# TMS320F280049 register map
Vendor: Texas Instruments; Series: C2000 F28004x; File version: 0.2.0-generated
Registers are 16-bit, read-write, reset 0x0 unless marked. A register's access mark holds for its fields unless they carry their own. Offsets are from the block's base; [hi:lo] are bit positions.

## ROMWAITSTATEREGS — ROM WAIT STATE Registers
Base 0x000BEA80
0x00 ROMWAITSTATE 32-bit — ROM Wait State Configuration Register
  [0] WSDISABLE — ROM Wait State Enable/Disable Control

## FLASHCTRLREGS — FLASH CTRL Registers
Base 0x000BF000
0x00 FRDCNTL 32-bit — Flash Read Control Register
  [14:11] RWAIT — Random Read Waitstate
0x3C FBAC 32-bit — Flash Bank Access Control Register
  [22:15] BAGP — Bank Active Grace Period
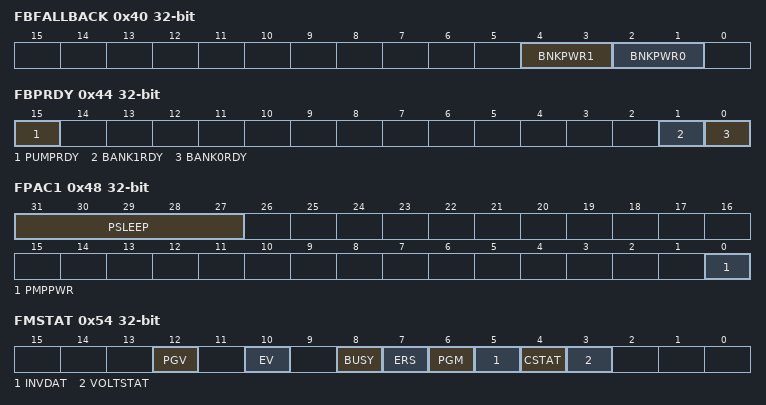
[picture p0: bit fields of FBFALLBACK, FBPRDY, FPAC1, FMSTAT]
0x40 FBFALLBACK 32-bit — Flash Bank Fallback Power Register
  [4:3] BNKPWR1 — Bank Power Mode of BANK1
  [2:1] BNKPWR0 — Bank Power Mode of BANK0
0x44 FBPRDY 32-bit — Flash Bank Pump Ready Register
  [15] PUMPRDY — Flash Pump Active Power Mode
  [1] BANK1RDY — Flash Bank Active Power State
  [0] BANK0RDY — Flash Bank Active Power State
0x48 FPAC1 32-bit — Flash Pump Access Control Register 1
  [31:27] PSLEEP — Pump Sleep Down Count
  [0] PMPPWR — Charge Pump Fallback Power Mode
0x4C FPAC2 32-bit — Flash Pump Access Control Register 2
  [30:15] PAGP — Pump Active Grace Period
0x54 FMSTAT 32-bit — Flash Module Status Register
  [12] PGV — Programming Verify Status
  [10] EV — Erase Verify Status
  [8] BUSY — Busy Bit
  [7] ERS — Erase Operation Status
  [6] PGM — Program Operation Status
  [5] INVDAT — Invalid Data
  [4] CSTAT — Command Fail Status
  [3] VOLTSTAT — Flash Pump Power Status
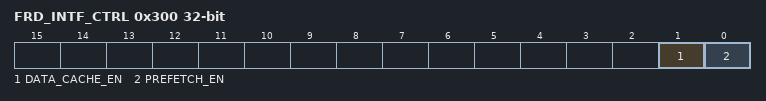
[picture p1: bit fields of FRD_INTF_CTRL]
0x300 FRD_INTF_CTRL 32-bit — Flash Read Interface Control Register
  [1] DATA_CACHE_EN — Data Cache Enable
  [0] PREFETCH_EN — Prefetch Enable

## FLASHECCREGS — FLASH ECC Registers
Base 0x000BF600
0x00 ECC_ENABLE 32-bit
  [6:3] ENABLE — Enable ECC
0x04 SINGLE_ERR_ADDR_LOW 32-bit — Single Error Address Low
  [31] ERR_ADDR_L — Lower 64 bit Single Bit Error Address
0x08 SINGLE_ERR_ADDR_HIGH 32-bit — Single Error Address High
  [31] ERR_ADDR_H — Upper 64 bit Single Bit Error Address
0x0C UNC_ERR_ADDR_LOW 32-bit — Uncorrectable Error Address Low
  [31] UNC_ERR_ADDR_L — Lower 64 bit Uncorrectable Error Address
0x10 UNC_ERR_ADDR_HIGH 32-bit — Uncorrectable Error Address High
  [31] UNC_ERR_ADDR_H — Upper 64 bit Uncorrectable Error Address
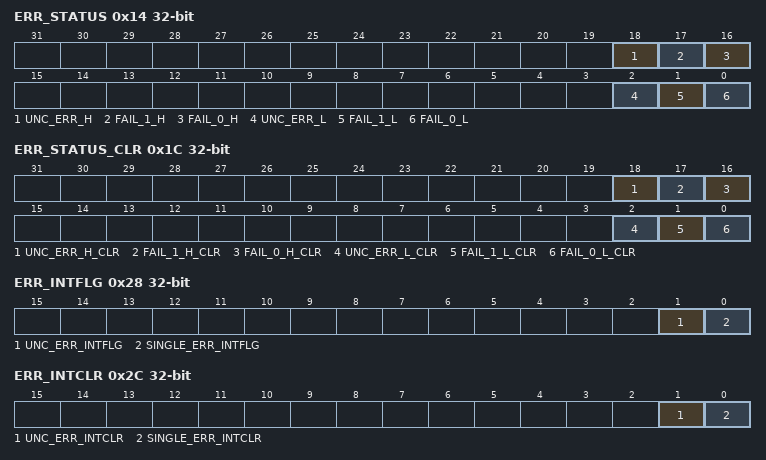
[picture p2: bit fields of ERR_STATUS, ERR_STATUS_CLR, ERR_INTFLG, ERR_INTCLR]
0x14 ERR_STATUS 32-bit — Error Status
  [18] UNC_ERR_H — Upper 64 bits Uncorrectable error occurred
  [17] FAIL_1_H — Upper 64bits Single Bit Error Corrected Value 1
  [16] FAIL_0_H — Upper 64bits Single Bit Error Corrected Value 0
  [2] UNC_ERR_L — Lower 64 bits Uncorrectable error occurred
  [1] FAIL_1_L — Lower 64bits Single Bit Error Corrected Value 1
  [0] FAIL_0_L — Lower 64bits Single Bit Error Corrected Value 0
0x18 ERR_POS 32-bit — Error Position
  [24] ERR_TYPE_H — Error Type in upper 64 bits
  [26:21] ERR_POS_H — Bit Position of Single bit Error in upper 64 bits
  [8] ERR_TYPE_L — Error Type in lower 64 bits
  [10:5] ERR_POS_L — Bit Position of Single bit Error in lower 64 bits
0x1C ERR_STATUS_CLR 32-bit — Error Status Clear
  [18] UNC_ERR_H_CLR — Upper 64 bits Uncorrectable error occurred Clear
  [17] FAIL_1_H_CLR — Upper 64bits Single Bit Error Corrected Value 1 Clear
  [16] FAIL_0_H_CLR — Upper 64bits Single Bit Error Corrected Value 0 Clear
  [2] UNC_ERR_L_CLR — Lower 64 bits Uncorrectable error occurred Clear
  [1] FAIL_1_L_CLR — Lower 64bits Single Bit Error Corrected Value 1 Clear
  [0] FAIL_0_L_CLR — Lower 64bits Single Bit Error Corrected Value 0 Clear
0x20 ERR_CNT 32-bit — Error Control
  [30:15] ERR_CNT — Error counter
0x24 ERR_THRESHOLD 32-bit — Error Threshold
  [30:15] ERR_THRESHOLD
0x28 ERR_INTFLG 32-bit — Error Interrupt Flag
  [1] UNC_ERR_INTFLG — Uncorrectable Interrupt Flag
  [0] SINGLE_ERR_INTFLG — Single Error Interrupt Flag
0x2C ERR_INTCLR 32-bit — Error Interrupt Flag Clear
  [1] UNC_ERR_INTCLR — Uncorrectable Interrupt Flag Clear
  [0] SINGLE_ERR_INTCLR — Single Error Interrupt Flag Clear
0x30 FDATAH_TEST 32-bit — Data High Test
  [31] FDATAH
0x34 FDATAL_TEST 32-bit — Data Low Test
  [31] FDATAL
0x38 FADDR_TEST 32-bit — ECC Test Address
  [26:21] ADDRH — ECC Address High
  [27:15] ADDRL — ECC Address Low
0x3C FECC_TEST 32-bit — ECC Test Address
  [14:7] ECC — ECC Control Bits
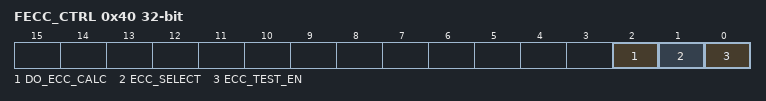
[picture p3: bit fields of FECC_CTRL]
0x40 FECC_CTRL 32-bit — ECC Control
  [2] DO_ECC_CALC — Enable ECC Calculation
  [1] ECC_SELECT — ECC Bit Select
  [0] ECC_TEST_EN — Enable ECC Test Logic
0x44 FOUTH_TEST 32-bit — Test Data Out High
  [31] DATAOUTH
0x48 FOUTL_TEST 32-bit — Test Data Out Low
  [31] DATAOUTL
0x4C FECC_STATUS 32-bit — ECC Status
  [8] ERR_TYPE — Holds Bit Position of 8 Check Bits of Error
  [12:7] DATA_ERR_POS — Holds Bit Position of Error
  [1] UNC_ERR — Test Result is Uncorrectable Error
  [0] SINGLE_ERR — Test Result is Single Bit Error
